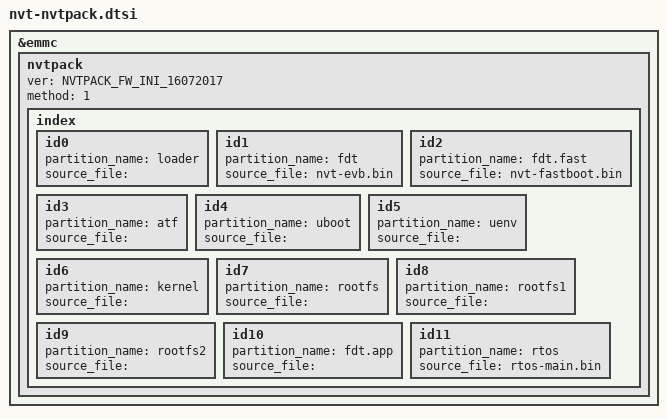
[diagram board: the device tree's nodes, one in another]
/*
 * Novatek Ltd. BSP part of dts
 */

&emmc {
	nvtpack {
		ver = "NVTPACK_FW_INI_16072017"; /* Fixed */
		method = <1>; /* Fixed */
		index {
			id0 { partition_name = "loader";      source_file = ""; }; /* Fixed */
			id1 { partition_name = "fdt";         source_file = "nvt-evb.bin"; }; /* Fixed */
			id2 { partition_name = "fdt.fast";    source_file = "nvt-fastboot.bin";	}; /* Fixed */
			id3 { partition_name = "atf";         source_file = ""; };
			id4 { partition_name = "uboot";	      source_file = ""; };
			id5 { partition_name = "uenv";	      source_file = ""; };
			id6 { partition_name = "kernel";      source_file = ""; };
			id7 { partition_name = "rootfs";      source_file = ""; };
			id8 { partition_name = "rootfs1";     source_file = ""; };
			id9 { partition_name = "rootfs2";     source_file = ""; };
			id10 { partition_name = "fdt.app";    source_file = ""; };
			id11 { partition_name = "rtos";       source_file = "rtos-main.bin"; };
		};
	};
};
